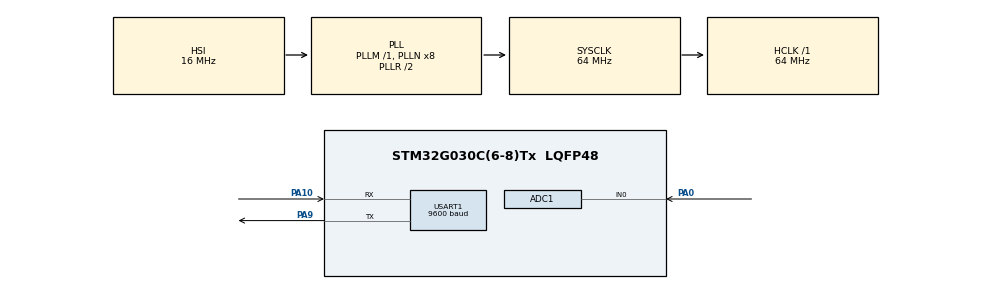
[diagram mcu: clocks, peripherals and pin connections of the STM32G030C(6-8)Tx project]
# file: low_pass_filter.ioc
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ADC1.Channel-0\#ChannelRegularConversion=ADC_CHANNEL_0
ADC1.ClockPrescaler=ADC_CLOCK_SYNC_PCLK_DIV4
ADC1.ContinuousConvMode=ENABLE
ADC1.NbrOfConversionFlag=1
ADC1.Rank-0\#ChannelRegularConversion=1
ADC1.SamplingTime-0\#ChannelRegularConversion=ADC_SAMPLINGTIME_COMMON_1
ADC1.SamplingTimeCommon1=ADC_SAMPLETIME_3CYCLES_5
ADC1.SamplingTimeCommon2=ADC_SAMPLETIME_3CYCLES_5
ADC1.SelectedChannel=ADC_CHANNEL_0
ADC1.master=1
Dma.ADC1.0.Direction=DMA_PERIPH_TO_MEMORY
Dma.ADC1.0.EventEnable=DISABLE
Dma.ADC1.0.Instance=DMA1_Channel1
Dma.ADC1.0.MemDataAlignment=DMA_MDATAALIGN_WORD
Dma.ADC1.0.MemInc=DMA_MINC_ENABLE
Dma.ADC1.0.Mode=DMA_CIRCULAR
Dma.ADC1.0.PeriphDataAlignment=DMA_PDATAALIGN_WORD
Dma.ADC1.0.PeriphInc=DMA_PINC_DISABLE
Dma.ADC1.0.Polarity=HAL_DMAMUX_REQ_GEN_RISING
Dma.ADC1.0.Priority=DMA_PRIORITY_LOW
Dma.ADC1.0.RequestNumber=1
Dma.ADC1.0.SignalID=NONE
Dma.ADC1.0.SyncEnable=DISABLE
Dma.ADC1.0.SyncPolarity=HAL_DMAMUX_SYNC_NO_EVENT
Dma.ADC1.0.SyncRequestNumber=1
Dma.ADC1.0.SyncSignalID=NONE
Dma.Request0=ADC1
Mcu.Family=STM32G0
Mcu.Name=STM32G030C(6-8)Tx
Mcu.Package=LQFP48
NVIC.DMA1_Channel1_IRQn=true\:0\:0\:false\:false\:true\:false\:true\:true
NVIC.USART1_IRQn=true\:0\:0\:false\:false\:true\:true\:true\:true
PA0.Mode=IN0
PA0.Signal=ADC1_IN0
PA10.GPIO_PuPd=GPIO_PULLUP
PA10.Mode=Asynchronous
PA10.Signal=USART1_RX
PA9.GPIO_PuPd=GPIO_PULLUP
PA9.Mode=Asynchronous
PA9.Signal=USART1_TX
ProjectManager.HeapSize=0x200
ProjectManager.StackSize=0x400
ProjectManager.TargetToolchain=STM32CubeIDE
RCC.ADCFreq_Value=64000000
RCC.AHBFreq_Value=64000000
RCC.CortexFreq_Value=64000000
RCC.EXTERNAL_CLOCK_VALUE=12288000
RCC.HCLKFreq_Value=64000000
RCC.HSE_VALUE=8000000
RCC.HSI_VALUE=16000000
RCC.LSE_VALUE=32768
RCC.SYSCLKFreq_VALUE=64000000
RCC.SYSCLKSource=RCC_SYSCLKSOURCE_PLLCLK
RCC.VCOOutputFreq_Value=128000000
USART1.BaudRate=9600
USART1.VirtualMode-Asynchronous=VM_ASYNC
board=custom

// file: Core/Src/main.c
/* USER CODE BEGIN Header */
/**
  ******************************************************************************
  * @file           : main.c
  * @brief          : Main program body
  ******************************************************************************
  * @attention
  *
  * Copyright (c) 2023 STMicroelectronics.
  * All rights reserved.
  *
  * This software is licensed under terms that can be found in the LICENSE file
  * in the root directory of this software component.
  * If no LICENSE file comes with this software, it is provided AS-IS.
  *
  ******************************************************************************
  */
/* USER CODE END Header */
#include "main.h"

/* USER CODE BEGIN Includes */
#include <stdbool.h>
#include <math.h>
/* USER CODE END Includes */

/* USER CODE BEGIN PTD */
typedef struct {
	float alpha;	// Smoothing factor
	float y_value[2];		// Output of IIR/RC Filter
} RCFilter;

// Top NTC Threshold - 50K
enum{
	// ADC Before Divided
	MIN_TOP_NTC 		= 3910,		// 10 derajat
	MAX_TOP_NTC 		= 606,		// 150 derajat
	// ADC After Divided
	TOPNTC_PLUS1		= 498,
	TOPNTC_PLUS20		= 476,
	TOPNTC_PLUS40		= 435,
	TOPNTC_PLUS60		= 371,
	TOPNTC_PLUS100		= 208,
	TOPNTC_PLUS150		= 76,
};
/* USER CODE END PTD */

/* USER CODE BEGIN PD */
#define LPF_ALPHA_COEF	      0.98f // Alpha coefficient
#define LPF_TIME_SAMPLING     20    // In milliseconds
/* USER CODE END PD */

ADC_HandleTypeDef hadc1;
DMA_HandleTypeDef hdma_adc1;

UART_HandleTypeDef huart1;

/* USER CODE BEGIN PV */
// Temperature voltage
const int tempMin40  = 483;	 const int tempMin20  = 424;
const int tempMin19	 = 423;  const int temp0	  = 316;
const int tempPls1	 = 310;  const int tempPls20  = 192;
const int tempPls21	 = 190;  const int tempPls40  = 107;
const int tempPls41	 = 104;	 const int tempPls60  = 56;
const int tempPls61	 = 55;	 const int tempPls80  = 30;
const int tempPls81	 = 29;	 const int tempPls100 = 17;
const int tempPls101 = 16;   const int tempPls120 = 10;
const int tempPls121 = 9;	 const int tempPls150 = 5;
/* USER CODE END PV */

void SystemClock_Config(void);
static void MX_GPIO_Init(void);
static void MX_DMA_Init(void);
static void MX_ADC1_Init(void);
static void MX_USART1_UART_Init(void);
/* USER CODE BEGIN PFP */
uint8_t tx_buffer[5];
uint32_t adcValue[1];
uint32_t RCfilter_lastTime = 0;
bool flagSendUART = false;
RCFilter ADC_LPF;
/* USER CODE END PFP */

/* USER CODE BEGIN 0 */

/**
 * @brief Apply filter to the given input value
 * @param:
 * 		filter			A struct for storing the computed alpha and filtered value
 * 		x_value			Input data to filter
 * @retval Filtered value
**/
uint16_t RC_Filter(RCFilter *filter, uint32_t x_value){
	filter->y_value[1] = filter->y_value[0];	// Shift output samples
	filter->y_value[0] = ((1 - filter->alpha) * x_value) + (filter->alpha * filter->y_value[1]);
	return (uint16_t)filter->y_value[0];
}

uint8_t ntc_temperature(uint16_t dividedADC)
{
	if(dividedADC <= TOPNTC_PLUS1 && dividedADC >= TOPNTC_PLUS20)
		return  ((-0.9011 * dividedADC) + 449.86);
	else if(dividedADC < TOPNTC_PLUS20 && dividedADC >= TOPNTC_PLUS40)
		return  ((-0.4833 * dividedADC) + 251.14);
	else if(dividedADC < TOPNTC_PLUS40 && dividedADC >= TOPNTC_PLUS60)
		return	((-0.3077 * dividedADC) + 174.59);
	else if(dividedADC < TOPNTC_PLUS60 && dividedADC >= TOPNTC_PLUS100)
		return 	((-0.2414 * dividedADC) + 149.79);
	else if(dividedADC < TOPNTC_PLUS100 && dividedADC >= TOPNTC_PLUS150)
		return 	((0.0012 * pow(dividedADC, 2)) - (0.7012 * dividedADC) + 195.54);
	return 0;
}

/**
 * @brief ADC DMA callback when buffer is full
 * @param:
 * 		hadc	ADC Peripheral
 * @retval None
**/
void HAL_ADC_ConvCpltCallback(ADC_HandleTypeDef *hadc)
{
	tx_buffer[0] = ntc_temperature(RC_Filter(&ADC_LPF,adcValue[0]/8));
	tx_buffer[1] = ntc_temperature(adcValue[0]/8);
}

/* USER CODE END 0 */

int main(void)
{

  /* MCU Configuration--------------------------------------------------------*/

  /* Reset of all peripherals, Initializes the Flash interface and the Systick. */
  HAL_Init();

  /* Configure the system clock */
  SystemClock_Config();

  /* Initialize all configured peripherals */
  MX_GPIO_Init();
  MX_DMA_Init();
  MX_ADC1_Init();
  MX_USART1_UART_Init();
  /* USER CODE BEGIN 2 */

  // Initialize RC Filter value
  ADC_LPF.alpha = LPF_ALPHA_COEF;
  ADC_LPF.y_value[0] = 0.0f;
  ADC_LPF.y_value[1] = 0.0f;

  HAL_ADC_Start_DMA(&hadc1, adcValue, 1);

  /* USER CODE END 2 */

  /* Infinite loop */
  /* USER CODE BEGIN WHILE */
  while (1)
  {
//	if(HAL_GetTick() - RCfilter_lastTime > 1000){
//		RCfilter_lastTime = HAL_GetTick();
//		HAL_UART_Transmit_IT(&huart1, tx_buffer, 2);
//		flagSendUART = false;
//	}

	  // Read ADC every 20 ms
	  if(HAL_GetTick() - RCfilter_lastTime > LPF_TIME_SAMPLING){
		  RCfilter_lastTime = HAL_GetTick();
		  HAL_ADC_Start_DMA(&hadc1, adcValue, 1);
	  }

    /* USER CODE END WHILE */

  }
}

void SystemClock_Config(void)
{
  RCC_OscInitTypeDef RCC_OscInitStruct = {0};
  RCC_ClkInitTypeDef RCC_ClkInitStruct = {0};

  /** Configure the main internal regulator output voltage
  */
  HAL_PWREx_ControlVoltageScaling(PWR_REGULATOR_VOLTAGE_SCALE1);

  /** Initializes the RCC Oscillators according to the specified parameters
  * in the RCC_OscInitTypeDef structure.
  */
  RCC_OscInitStruct.OscillatorType = RCC_OSCILLATORTYPE_HSI;
  RCC_OscInitStruct.HSIState = RCC_HSI_ON;
  RCC_OscInitStruct.HSIDiv = RCC_HSI_DIV1;
  RCC_OscInitStruct.HSICalibrationValue = RCC_HSICALIBRATION_DEFAULT;
  RCC_OscInitStruct.PLL.PLLState = RCC_PLL_ON;
  RCC_OscInitStruct.PLL.PLLSource = RCC_PLLSOURCE_HSI;
  RCC_OscInitStruct.PLL.PLLM = RCC_PLLM_DIV1;
  RCC_OscInitStruct.PLL.PLLN = 8;
  RCC_OscInitStruct.PLL.PLLP = RCC_PLLP_DIV2;
  RCC_OscInitStruct.PLL.PLLR = RCC_PLLR_DIV2;
  if (HAL_RCC_OscConfig(&RCC_OscInitStruct) != HAL_OK)
  {
    Error_Handler();
  }

  /** Initializes the CPU, AHB and APB buses clocks
  */
  RCC_ClkInitStruct.ClockType = RCC_CLOCKTYPE_HCLK|RCC_CLOCKTYPE_SYSCLK
                              |RCC_CLOCKTYPE_PCLK1;
  RCC_ClkInitStruct.SYSCLKSource = RCC_SYSCLKSOURCE_PLLCLK;
  RCC_ClkInitStruct.AHBCLKDivider = RCC_SYSCLK_DIV1;
  RCC_ClkInitStruct.APB1CLKDivider = RCC_HCLK_DIV1;

  if (HAL_RCC_ClockConfig(&RCC_ClkInitStruct, FLASH_LATENCY_2) != HAL_OK)
  {
    Error_Handler();
  }
}

static void MX_ADC1_Init(void)
{

  ADC_ChannelConfTypeDef sConfig = {0};

  /** Configure the global features of the ADC (Clock, Resolution, Data Alignment and number of conversion)
  */
  hadc1.Instance = ADC1;
  hadc1.Init.ClockPrescaler = ADC_CLOCK_SYNC_PCLK_DIV4;
  hadc1.Init.Resolution = ADC_RESOLUTION_12B;
  hadc1.Init.DataAlign = ADC_DATAALIGN_RIGHT;
  hadc1.Init.ScanConvMode = ADC_SCAN_DISABLE;
  hadc1.Init.EOCSelection = ADC_EOC_SINGLE_CONV;
  hadc1.Init.LowPowerAutoWait = DISABLE;
  hadc1.Init.LowPowerAutoPowerOff = DISABLE;
  hadc1.Init.ContinuousConvMode = ENABLE;
  hadc1.Init.NbrOfConversion = 1;
  hadc1.Init.ExternalTrigConv = ADC_SOFTWARE_START;
  hadc1.Init.ExternalTrigConvEdge = ADC_EXTERNALTRIGCONVEDGE_NONE;
  hadc1.Init.DMAContinuousRequests = DISABLE;
  hadc1.Init.Overrun = ADC_OVR_DATA_PRESERVED;
  hadc1.Init.SamplingTimeCommon1 = ADC_SAMPLETIME_3CYCLES_5;
  hadc1.Init.SamplingTimeCommon2 = ADC_SAMPLETIME_3CYCLES_5;
  hadc1.Init.OversamplingMode = DISABLE;
  hadc1.Init.TriggerFrequencyMode = ADC_TRIGGER_FREQ_HIGH;
  if (HAL_ADC_Init(&hadc1) != HAL_OK)
  {
    Error_Handler();
  }

  /** Configure Regular Channel
  */
  sConfig.Channel = ADC_CHANNEL_0;
  sConfig.Rank = ADC_REGULAR_RANK_1;
  sConfig.SamplingTime = ADC_SAMPLINGTIME_COMMON_1;
  if (HAL_ADC_ConfigChannel(&hadc1, &sConfig) != HAL_OK)
  {
    Error_Handler();
  }

}

static void MX_USART1_UART_Init(void)
{

  huart1.Instance = USART1;
  huart1.Init.BaudRate = 9600;
  huart1.Init.WordLength = UART_WORDLENGTH_8B;
  huart1.Init.StopBits = UART_STOPBITS_1;
  huart1.Init.Parity = UART_PARITY_NONE;
  huart1.Init.Mode = UART_MODE_TX_RX;
  huart1.Init.HwFlowCtl = UART_HWCONTROL_NONE;
  huart1.Init.OverSampling = UART_OVERSAMPLING_16;
  huart1.Init.OneBitSampling = UART_ONE_BIT_SAMPLE_DISABLE;
  huart1.Init.ClockPrescaler = UART_PRESCALER_DIV1;
  huart1.AdvancedInit.AdvFeatureInit = UART_ADVFEATURE_NO_INIT;
  if (HAL_UART_Init(&huart1) != HAL_OK)
  {
    Error_Handler();
  }
  if (HAL_UARTEx_SetTxFifoThreshold(&huart1, UART_TXFIFO_THRESHOLD_1_8) != HAL_OK)
  {
    Error_Handler();
  }
  if (HAL_UARTEx_SetRxFifoThreshold(&huart1, UART_RXFIFO_THRESHOLD_1_8) != HAL_OK)
  {
    Error_Handler();
  }
  if (HAL_UARTEx_DisableFifoMode(&huart1) != HAL_OK)
  {
    Error_Handler();
  }

}

static void MX_DMA_Init(void)
{

  /* DMA controller clock enable */
  __HAL_RCC_DMA1_CLK_ENABLE();

  /* DMA interrupt init */
  /* DMA1_Channel1_IRQn interrupt configuration */
  HAL_NVIC_SetPriority(DMA1_Channel1_IRQn, 0, 0);
  HAL_NVIC_EnableIRQ(DMA1_Channel1_IRQn);

}

static void MX_GPIO_Init(void)
{

  /* GPIO Ports Clock Enable */
  __HAL_RCC_GPIOA_CLK_ENABLE();

}

void Error_Handler(void)
{
  __disable_irq();
  while (1)
  {
  }
}
